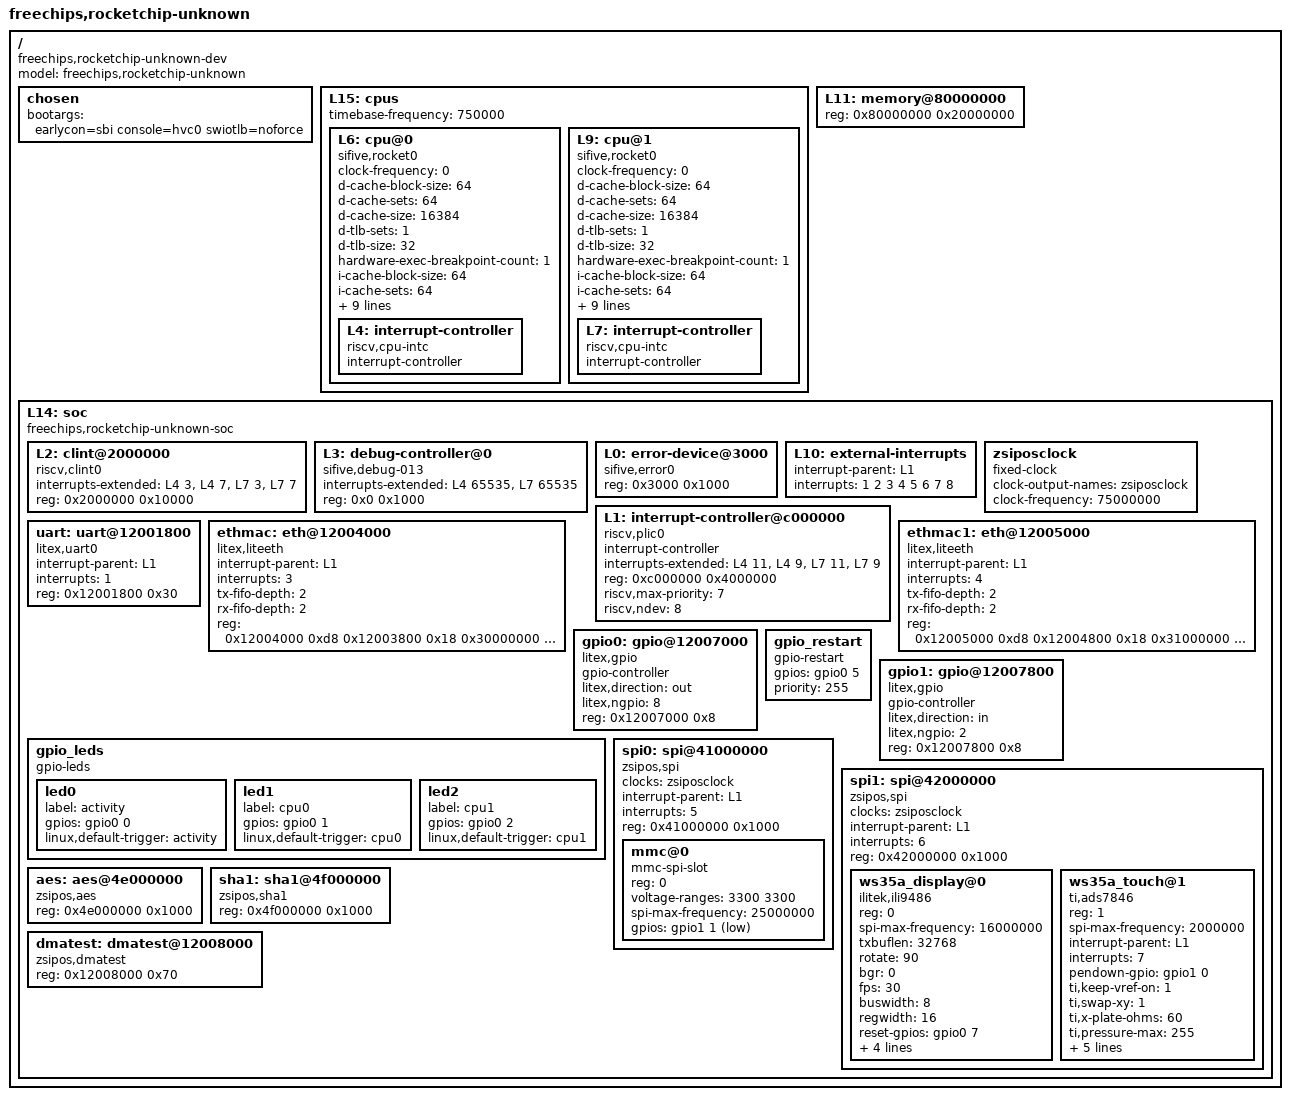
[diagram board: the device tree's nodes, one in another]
/dts-v1/;

/ {
	#address-cells = <1>;
	#size-cells = <1>;
	compatible = "freechips,rocketchip-unknown-dev";
	model = "freechips,rocketchip-unknown";
	chosen {
		bootargs = "earlycon=sbi console=hvc0 swiotlb=noforce";
	};
	L15: cpus {
		#address-cells = <1>;
		#size-cells = <0>;
		timebase-frequency = <750000>;
		L6: cpu@0 {
			clock-frequency = <0>;
			compatible = "sifive,rocket0", "riscv";
			d-cache-block-size = <64>;
			d-cache-sets = <64>;
			d-cache-size = <16384>;
			d-tlb-sets = <1>;
			d-tlb-size = <32>;
			device_type = "cpu";
			hardware-exec-breakpoint-count = <1>;
			i-cache-block-size = <64>;
			i-cache-sets = <64>;
			i-cache-size = <16384>;
			i-tlb-sets = <1>;
			i-tlb-size = <32>;
			mmu-type = "riscv,sv39";
			next-level-cache = <&L11>;
			reg = <0x0>;
			riscv,isa = "rv64imafdc";
			riscv,pmpregions = <8>;
			status = "okay";
			tlb-split;
			L4: interrupt-controller {
				#interrupt-cells = <1>;
				compatible = "riscv,cpu-intc";
				interrupt-controller;
			};
		};
		L9: cpu@1 {
			clock-frequency = <0>;
			compatible = "sifive,rocket0", "riscv";
			d-cache-block-size = <64>;
			d-cache-sets = <64>;
			d-cache-size = <16384>;
			d-tlb-sets = <1>;
			d-tlb-size = <32>;
			device_type = "cpu";
			hardware-exec-breakpoint-count = <1>;
			i-cache-block-size = <64>;
			i-cache-sets = <64>;
			i-cache-size = <16384>;
			i-tlb-sets = <1>;
			i-tlb-size = <32>;
			mmu-type = "riscv,sv39";
			next-level-cache = <&L11>;
			reg = <0x1>;
			riscv,isa = "rv64imafdc";
			riscv,pmpregions = <8>;
			status = "okay";
			tlb-split;
			L7: interrupt-controller {
				#interrupt-cells = <1>;
				compatible = "riscv,cpu-intc";
				interrupt-controller;
			};
		};
	};
	L11: memory@80000000 {
		device_type = "memory";
		reg = <0x80000000 0x20000000>;
	};
	L14: soc {
		#address-cells = <1>;
		#size-cells = <1>;
		compatible = "freechips,rocketchip-unknown-soc", "simple-bus";
		ranges;
		L2: clint@2000000 {
			compatible = "riscv,clint0";
			interrupts-extended = <&L4 3 &L4 7 &L7 3 &L7 7>;
			reg = <0x2000000 0x10000>;
			reg-names = "control";
		};
		L3: debug-controller@0 {
			compatible = "sifive,debug-013", "riscv,debug-013";
			interrupts-extended = <&L4 65535 &L7 65535>;
			reg = <0x0 0x1000>;
			reg-names = "control";
		};
		L0: error-device@3000 {
			compatible = "sifive,error0";
			reg = <0x3000 0x1000>;
		};
		L10: external-interrupts {
			interrupt-parent = <&L1>;
			interrupts = <1 2 3 4 5 6 7 8>;
		};
		L1: interrupt-controller@c000000 {
			#interrupt-cells = <1>;
			compatible = "riscv,plic0";
			interrupt-controller;
			interrupts-extended = <&L4 11 &L4 9 &L7 11 &L7 9>;
			reg = <0xc000000 0x4000000>;
			reg-names = "control";
			riscv,max-priority = <7>;
			riscv,ndev = <8>;
		};
		zsiposclock: zsiposclock {
			#clock-cells = <0>;
			compatible = "fixed-clock";
			clock-output-names = "zsiposclock";
			clock-frequency = <75000000>;
		};
		uart: uart@12001800 {
			compatible = "litex,uart0";
			interrupt-parent = <&L1>;
			interrupts = <1>;
			reg = <0x12001800 0x30>;
		};
		ethmac: eth@12004000 {
			compatible = "litex,liteeth";
			interrupt-parent = <&L1>;
			interrupts = <3>;
			tx-fifo-depth = <2>;
			rx-fifo-depth = <2>;
			reg = 	<0x12004000 0xd8
				 0x12003800 0x18
				 0x30000000 0x2000>;
		};
		ethmac1: eth@12005000 {
			compatible = "litex,liteeth";
			interrupt-parent = <&L1>;
			interrupts = <4>;
			tx-fifo-depth = <2>;
			rx-fifo-depth = <2>;
			reg = 	<0x12005000 0xd8
				 0x12004800 0x18
				 0x31000000 0x2000>;
		};
		gpio0: gpio@12007000 {
			#gpio-cells = <2>;
			compatible = "litex,gpio";
			gpio-controller;
			litex,direction = "out";
			litex,ngpio = <8>;
			reg = <0x12007000 0x8>;
		};
		gpio_leds {
			compatible = "gpio-leds";
			led0 {
				label = "activity";
				gpios = <&gpio0 0 0>;
				linux,default-trigger = "activity";
			};
			led1 {
				label = "cpu0";
				gpios = <&gpio0 1 0>;
				linux,default-trigger = "cpu0";
			};
			led2 {
				label = "cpu1";
				gpios = <&gpio0 2 0>;
				linux,default-trigger = "cpu1";
			};
		};
		gpio_restart {
			compatible = "gpio-restart";
				gpios = <&gpio0 5 0>;
				priority = <255>;
		};
		gpio1: gpio@12007800 {
			#gpio-cells = <2>;
			compatible = "litex,gpio";
			gpio-controller;
			litex,direction = "in";
			litex,ngpio = <2>;
			reg = <0x12007800 0x8>;
		};
		spi0: spi@41000000 {
			#address-cells = <1>;
			#size-cells = <0>;
			compatible = "zsipos,spi";
			clocks = <&zsiposclock>;
			interrupt-parent = <&L1>;
			interrupts = <5>;
			reg = <0x41000000 0x1000>;
			mmc@0 {
				compatible = "mmc-spi-slot";
				reg = <0>;
				voltage-ranges = <3300 3300>;
				spi-max-frequency = <25000000>;
				gpios = <&gpio1 1 1>;
			};
		};
		spi1: spi@42000000 {
			#address-cells = <1>;
			#size-cells = <0>;
			compatible = "zsipos,spi";
			clocks = <&zsiposclock>;
			interrupt-parent = <&L1>;
			interrupts = <6>;
			reg = <0x42000000 0x1000>;
			ws35a_display@0 {
				compatible = "ilitek,ili9486";
				reg = <0>;
				spi-max-frequency = <16000000>;
				txbuflen = <32768>;
				rotate = <90>;
				bgr = <0>;
				fps = <30>;
				buswidth = <8>;
				regwidth = <16>;
				reset-gpios = <&gpio0 7 0>;
				dc-gpios = <&gpio0 6 0>;
				debug = <0>;
				init = <0x10000b0 0x00
					0x1000011
					0x20000ff
					0x100003a 0x55
					0x1000036 0x28
					0x10000c2 0x44
					0x10000c5 0x00 0x00 0x00 0x00
					0x10000e0 0x0f 0x1f 0x1c 0x0c 0x0f 0x08 0x48 0x98 0x37 0x0a 0x13 0x04 0x11 0x0d 0x00
					0x10000e1 0x0f 0x32 0x2e 0x0b 0x0d 0x05 0x47 0x75 0x37 0x06 0x10 0x03 0x24 0x20 0x00
					0x10000e2 0x0f 0x32 0x2e 0x0b 0x0d 0x05 0x47 0x75 0x37 0x06 0x10 0x03 0x24 0x20 0x00
					0x1000036 0x28
					0x1000011
					0x1000029>;
			};
			ws35a_touch@1 {
				compatible = "ti,ads7846";
				reg = <1>;
				spi-max-frequency = <2000000>;
				interrupt-parent = <&L1>;
				interrupts = <7>;
				pendown-gpio = <&gpio1 0 0>;
				ti,keep-vref-on = <1>;
				ti,swap-xy = <1>;
				ti,x-plate-ohms = /bits/ 16 <60>;
				ti,pressure-max = /bits/ 16 <255>;
				ti,x-min = /bits/ 16 <200>;
				ti,x-max = /bits/ 16 <3900>;
				ti,y-min = /bits/ 16 <200>;
				ti,y-max = /bits/ 16 <3900>;
				wakeup-source;
			};
		};
		aes: aes@4e000000 {
			compatible = "zsipos,aes";
			reg = <0x4e000000 0x1000>;
		};
		sha1: sha1@4f000000 {
			compatible = "zsipos,sha1";
			reg = <0x4f000000 0x1000>;
		};
		dmatest: dmatest@12008000 {
			compatible = "zsipos,dmatest";
			reg = <0x12008000 0x70>;
		};
	};
};
